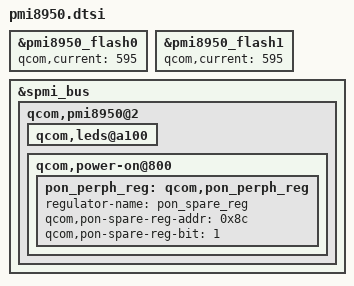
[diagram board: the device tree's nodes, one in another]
/*
 * Copyright (c) 2015-2017, The Linux Foundation. All rights reserved.
 *
 * This program is free software; you can redistribute it and/or modify
 * it under the terms of the GNU General Public License version 2 and
 * only version 2 as published by the Free Software Foundation.
 *
 * This program is distributed in the hope that it will be useful,
 * but WITHOUT ANY WARRANTY; without even the implied warranty of
 * MERCHANTABILITY or FITNESS FOR A PARTICULAR PURPOSE.  See the
 * GNU General Public License for more details.
 */

&pmi8950_flash0 {
	qcom,current = <595>;
};

&pmi8950_flash1 {
	qcom,current = <595>;
};

&spmi_bus {
	qcom,pmi8950@2 {
		qcom,leds@a100 {
			/delete-property/ status;
			/delete-node/ qcom,led_mpp_2;
		};

		qcom,power-on@800 {
			pon_perph_reg: qcom,pon_perph_reg {
				regulator-name = "pon_spare_reg";
				qcom,pon-spare-reg-addr = <0x8c>;
				qcom,pon-spare-reg-bit = <1>;
			};
		};
	};
};
